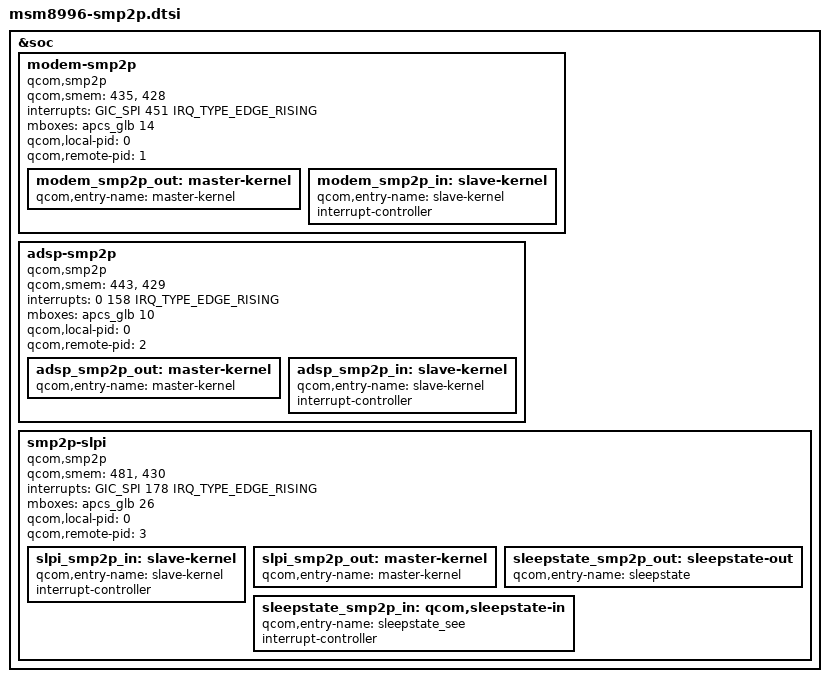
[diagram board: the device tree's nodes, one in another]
/* Copyright (c) 2014-2015, The Linux Foundation. All rights reserved.
 *
 * This program is free software; you can redistribute it and/or modify
 * it under the terms of the GNU General Public License version 2 and
 * only version 2 as published by the Free Software Foundation.
 *
 * This program is distributed in the hope that it will be useful,
 * but WITHOUT ANY WARRANTY; without even the implied warranty of
 * MERCHANTABILITY or FITNESS FOR A PARTICULAR PURPOSE.  See the
 * GNU General Public License for more details.
 */

#include <dt-bindings/interrupt-controller/arm-gic.h>

&soc {
	modem-smp2p {
		compatible = "qcom,smp2p";
		qcom,smem = <435>, <428>;

		interrupts = <GIC_SPI 451 IRQ_TYPE_EDGE_RISING>;

		mboxes = <&apcs_glb 14>;

		qcom,local-pid = <0>;
		qcom,remote-pid = <1>;

		modem_smp2p_out: master-kernel {
			qcom,entry-name = "master-kernel";
			#qcom,smem-state-cells = <1>;
		};

		modem_smp2p_in: slave-kernel {
			qcom,entry-name = "slave-kernel";

			interrupt-controller;
			#interrupt-cells = <2>;
		};
	};


	adsp-smp2p {
		compatible = "qcom,smp2p";
		qcom,smem = <443>, <429>;

		interrupts = <0 158 IRQ_TYPE_EDGE_RISING>;

		mboxes = <&apcs_glb 10>;

		qcom,local-pid = <0>;
		qcom,remote-pid = <2>;

		adsp_smp2p_out: master-kernel {
			qcom,entry-name = "master-kernel";
			#qcom,smem-state-cells = <1>;
		};

		adsp_smp2p_in: slave-kernel {
			qcom,entry-name = "slave-kernel";

			interrupt-controller;
			#interrupt-cells = <2>;
		};
	};

	smp2p-slpi {
		compatible = "qcom,smp2p";
		qcom,smem = <481>, <430>;

		interrupts = <GIC_SPI 178 IRQ_TYPE_EDGE_RISING>;

		mboxes = <&apcs_glb 26>;

		qcom,local-pid = <0>;
		qcom,remote-pid = <3>;

		slpi_smp2p_in: slave-kernel {
			qcom,entry-name = "slave-kernel";
			interrupt-controller;
			#interrupt-cells = <2>;
		};

		slpi_smp2p_out: master-kernel {
			qcom,entry-name = "master-kernel";
			#qcom,smem-state-cells = <1>;
		};

		sleepstate_smp2p_out: sleepstate-out {
			qcom,entry-name = "sleepstate";
			#qcom,smem-state-cells = <1>;
		};

		sleepstate_smp2p_in: qcom,sleepstate-in {
			qcom,entry-name = "sleepstate_see";
			interrupt-controller;
			#interrupt-cells = <2>;
		};
	};
};
